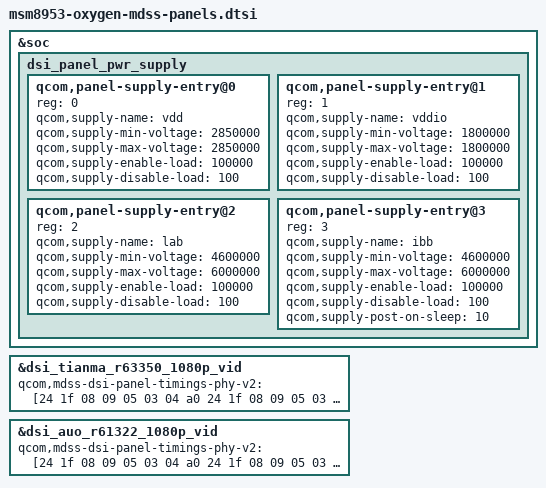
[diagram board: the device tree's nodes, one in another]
/*
 * Copyright (c) 2015-2018, The Linux Foundation. All rights reserved.
 *
 * This program is free software; you can redistribute it and/or modify
 * it under the terms of the GNU General Public License version 2 and
 * only version 2 as published by the Free Software Foundation.
 *
 * This program is distributed in the hope that it will be useful,
 * but WITHOUT ANY WARRANTY; without even the implied warranty of
 * MERCHANTABILITY or FITNESS FOR A PARTICULAR PURPOSE.  See the
 * GNU General Public License for more details.
 */

#include "dsi-panel-tianma-r63350-1080p-video.dtsi"
#include "dsi-panel-auo-r61322-1080p-video.dtsi"

&soc {
	dsi_panel_pwr_supply: dsi_panel_pwr_supply {
		#address-cells = <1>;
		#size-cells = <0>;

		qcom,panel-supply-entry@0 {
			reg = <0>;
			qcom,supply-name = "vdd";
			qcom,supply-min-voltage = <2850000>;
			qcom,supply-max-voltage = <2850000>;
			qcom,supply-enable-load = <100000>;
			qcom,supply-disable-load = <100>;
		};

		qcom,panel-supply-entry@1 {
			reg = <1>;
			qcom,supply-name = "vddio";
			qcom,supply-min-voltage = <1800000>;
			qcom,supply-max-voltage = <1800000>;
			qcom,supply-enable-load = <100000>;
			qcom,supply-disable-load = <100>;
		};

		qcom,panel-supply-entry@2 {
			reg = <2>;
			qcom,supply-name = "lab";
			qcom,supply-min-voltage = <4600000>;
			qcom,supply-max-voltage = <6000000>;
			qcom,supply-enable-load = <100000>;
			qcom,supply-disable-load = <100>;
		};

		qcom,panel-supply-entry@3 {
			reg = <3>;
			qcom,supply-name = "ibb";
			qcom,supply-min-voltage = <4600000>;
			qcom,supply-max-voltage = <6000000>;
			qcom,supply-enable-load = <100000>;
			qcom,supply-disable-load = <100>;
			qcom,supply-post-on-sleep = <10>;
		};
	};
};

&dsi_tianma_r63350_1080p_vid {
	qcom,mdss-dsi-panel-timings-phy-v2 = [24 1f 08 09 05 03 04 a0
		24 1f 08 09 05 03 04 a0
		24 1f 08 09 05 03 04 a0
		24 1f 08 09 05 03 04 a0
		24 1b 08 09 05 03 04 a0];
};

&dsi_auo_r61322_1080p_vid {
	qcom,mdss-dsi-panel-timings-phy-v2 = [24 1f 08 09 05 03 04 a0
		24 1f 08 09 05 03 04 a0
		24 1f 08 09 05 03 04 a0
		24 1f 08 09 05 03 04 a0
		24 1b 08 09 05 03 04 a0];
};
